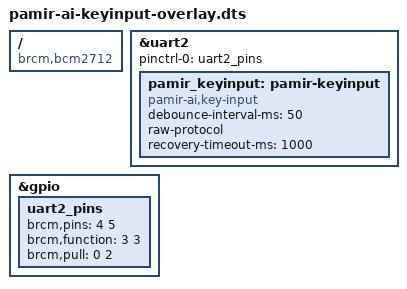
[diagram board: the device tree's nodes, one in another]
// SPDX-License-Identifier: GPL-2.0-only
/*
 * Device Tree overlay for Pamir AI Key Input via serial
 * Uses UART2 (ttyAMA2) for communication with RP2040
 */

/dts-v1/;
/plugin/;

/ {
	compatible = "brcm,bcm2712";

	fragment@0 {
		target = <&uart2>;
		__overlay__ {
			status = "okay";
			pinctrl-names = "default";
			pinctrl-0 = <&uart2_pins>;
		};
	};

	fragment@1 {
		target = <&uart2>;
		__overlay__ {
			pamir_keyinput: pamir-keyinput {
				compatible = "pamir-ai,key-input";
				status = "okay";
				debounce-interval-ms = <50>;  /* Debounce time in ms */
				raw-protocol;                 /* Enable raw byte protocol */
				recovery-timeout-ms = <1000>; /* UART recovery timeout */
			};
		};
	};

	/* Configure UART2 pins */
	fragment@2 {
		target = <&gpio>;
		__overlay__ {
			uart2_pins: uart2_pins {
				brcm,pins = <4 5>; /* TX on GPIO4, RX on GPIO5 */
				brcm,function = <3 3>; /* ALT4 = 3 */
				brcm,pull = <0 2>; /* OFF = 0, UP = 2 */
			};
		};
	};

	__overrides__ {
		debounce = <&pamir_keyinput>,"debounce-interval-ms:0";
		raw_protocol = <&pamir_keyinput>,"raw-protocol?";
		report_press_only = <&pamir_keyinput>,"report-press-only?";
		recovery_timeout = <&pamir_keyinput>,"recovery-timeout-ms:0";
	};
}; 
